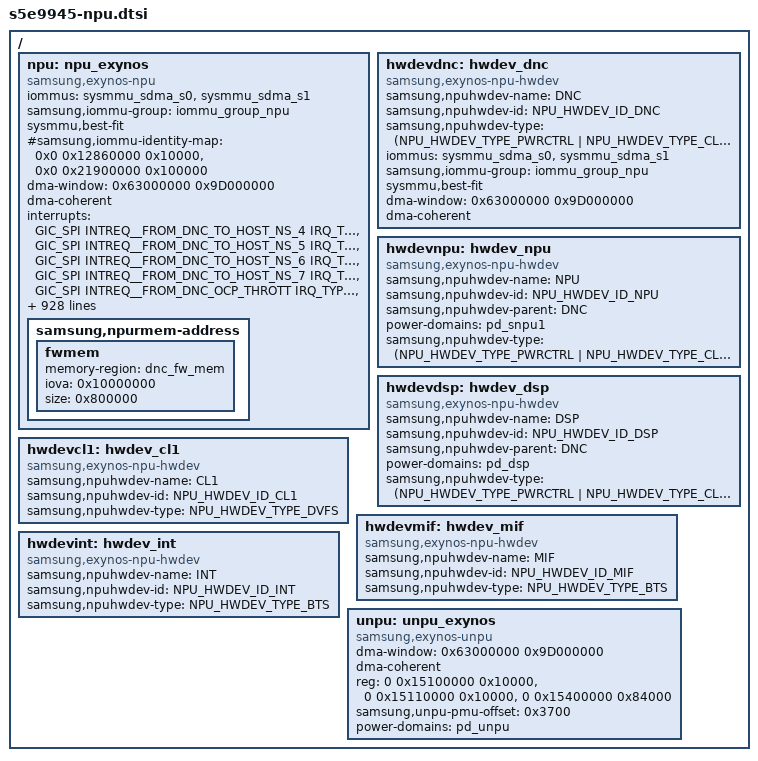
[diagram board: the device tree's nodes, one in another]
/*
 * SAMSUNG EXYNOS9945 NPU device tree source
 *
 * Copyright (c) 2023 Samsung Electronics Co., Ltd.
 *		http://www.samsung.com
 *
 * SAMSUNG EXYNOS9945 NPU device nodes are listed in this file.
 * EXYNOS based board files can include this file and provide
 * values for board specfic bindings.
 *
 * This program is free software; you can redistribute it and/or modify
 * it under the terms of the GNU General Public License version 2 as
 * published by the Free Software Foundation.
 */
#include <dt-bindings/clock/s5e9945.h>
#include <dt-bindings/soc/samsung/s5e9945-npu.h>

/ {
	npu: npu_exynos {
		compatible = "samsung,exynos-npu";
		iommus = <&sysmmu_sdma_s0>, <&sysmmu_sdma_s1>;
		samsung,iommu-group = <&iommu_group_npu>;
		sysmmu,best-fit;
		#samsung,iommu-identity-map = <0x0 0x12860000 0x10000>, <0x0 0x21900000 0x100000>;
		#dma-address-cells = <1>;
		#dma-size-cells = <1>;
		dma-window = <0x63000000 0x9D000000>;
		dma-coherent;

		interrupts =
			<GIC_SPI INTREQ__FROM_DNC_TO_HOST_NS_4 IRQ_TYPE_LEVEL_HIGH>,
			<GIC_SPI INTREQ__FROM_DNC_TO_HOST_NS_5 IRQ_TYPE_LEVEL_HIGH>,
			<GIC_SPI INTREQ__FROM_DNC_TO_HOST_NS_6 IRQ_TYPE_LEVEL_HIGH>,
			<GIC_SPI INTREQ__FROM_DNC_TO_HOST_NS_7 IRQ_TYPE_LEVEL_HIGH>,
			<GIC_SPI INTREQ__FROM_DNC_OCP_THROTT IRQ_TYPE_LEVEL_HIGH>,
			<GIC_SPI INTREQ__HTU_GNPU1 IRQ_TYPE_LEVEL_HIGH>;

		samsung,npusys-corenum = <2>;
		/* refer to npu-system.h for memory names
		 * you can add init settings for each memory area
		 */
		samsung,npumem-address = /* 0 start      size */
			<0 0x20000000 0x100000>,
			<0 0x20100000 0x100000>,
			<0 0x20200000 0x100000>,
			<0 0x20300000 0x100000>,
			<0 0x20400000 0x100000>,
			<0 0x20500000 0x100000>,
			<0 0x20600000 0x100000>,

			<0 0x21000000 0x200000>,
			<0 0x21200000 0x200000>,
			<0 0x21400000 0x100000>,
			<0 0x21500000 0x100000>,
			<0 0x21600000 0x100000>,
			<0 0x21700000 0x100000>,
			<0 0x21800000 0x100000>,
			<0 0x21900000 0x100000>,

			<0 0x12860000 0x10000>,

			<0 0x22B00000 0x100000>,

			<0 0x400D000 0x1000>,
			<0 0x400B000 0x1000>,
			<0 0x400C000 0x1000>,
			<0x50640000 0x100C0110 0x1000>, /* 0x5064_0000 is right by fw side, 100? 110? */

			<0 0x20020000 0x1000>,
			<0 0x2002084C 0x100>,
			<0 0x20022000 0x4000>,
			<0 0x20020838 0x100>,
			<0 0x210D0000 0x1000>,
			<0 0x216D0000 0x1000>,

			<0 0x11100000 0x200000>,
			<2 0x11300000 0x1000000>,
			<0 0x13300000 0x800000>,
			<0 0x14000000 0x1000000>,
			<0 0x10D00000 0x100000>,
			<0 0x10E00000 0x200000>,
			<0 0x11000000 0x1000>,
			<0 0x11001000 0x7000>,
			<0 0x11008000 0xF8000>,
			<0 0x22000000 0x40000000>,
			<0 0x22000000 0x20000000>,
			<0 0x42000000 0x20000000>,
			<0 0x0 0x2800>;
		samsung,npumem-names =
				"sfrdnc",	"SFR",
				"sfrsdma",	"SFR",
				"sfrgnpu0",	"SFR",
				"sfrgnpu1",	"SFR",
				"sfrdsp0",	"SFR",
				"sfrsnpu0",	"SFR",
				"sfrsnpu1",	"SFR",

				"sfrblkdnc",	"SFR",
				"sfrblksdma",	"SFR",
				"sfrblkdsp0",	"SFR",
				"sfrblkgnpu0",	"SFR",
				"sfrblkgnpu1",	"SFR",
				"sfrblksnpu0",	"SFR",
				"sfrblksnpu1",	"SFR",
				"sfrblknpumem",	"SFR",

				"sfrpmualive",	"SFR",

				"sfrfreq",	"SFR",

				"sfrcoresight",	"SFR",
				"sfrstm",	"SFR",
				"sfrstm1",	"SFR",
				"sfrmctg",	"SFR",

				"sfrmbox",	"SFR",
				"sfrmbox0",	"SFR",
				"sfrmbox1",	"SFR",
				"sfrmbox2",	"SFR",
				"htudnc",	"SFR",
				"htugnpu1",	"SFR",

				"fwmbox",	"fwmbox",
				"llc",		"llc",
				"fwunittest",	"fwunittest",
				"ivp_pm",	"dsp_ivp_pm.bin",
				"dl_out",	"dl_out",
				"dsp_mem",	"dsp_mem",
				"dhcp",		"dhcp",
				"ivp_dm",	"dsp_ivp_dm.bin",
				"fwlog",	"fwlog",
				"CHUNK_IMB",	"IMB",
				"CHUNK_IMBl",	"IMB",
				"CHUNK_IMBh",   "IMB",
				"CMDQ_TABLE",	"";

		/* examples of memory area init
		 *	offset,	val,	mask,
		 * samsung,npumem-baaw =
		 *	<0x00, 0x017B00, 0xFFFFFF>,
		 *	<0x00, 0x017B40, 0xFFFFFF>,
		 *	...;
		 */

		/* examples of reg cmd
		 *	sfr : name of memory area
		 *	data :
		 *	<rw	offset	val	mask	mdelay>,
		 */

		samsung,npucmd-acgennpum-sfr =
			"sfrblknpumem";
		samsung,npucmd-acgennpum-data =
			<1	0x800	0x301FF0BF	0xFFFFFFFF	0>;

		samsung,npucmd-acgdisnpum-sfr =
			"sfrblkdnc",
			"sfrblksdma",
			"sfrblknpumem",
			"sfrblkgnpu0",
			"sfrblkgnpu1",
			"sfrblksnpu0",
			"sfrblksnpu1";
		samsung,npucmd-acgdisnpum-data =
			<1	0x800	0xF01FF0BF	0xFFFFFFFF	0>,
			<1	0x800	0xF01FF0BF	0xFFFFFFFF	0>,
			<1	0x800	0x0		0xFFFFFFFF	0>,
			<1	0x800	0xF01FF0BF	0xFFFFFFFF	0>,
			<1	0x800	0xF01FF0BF	0xFFFFFFFF	0>,
			<1	0x800	0xF01FF0BF	0xFFFFFFFF	0>,
			<1	0x800	0xF01FF0BF	0xFFFFFFFF	0>;

		samsung,npucmd-acgendsp-sfr =
			"sfrblkdsp0";
		samsung,npucmd-acgendsp-data =
			<1	0x800	0xF01FF0BF	0xFFFFFFFF	0>;

		samsung,npucmd-acgenall-sfr =
			"sfrblkdnc",
			"sfrblksdma",
			"sfrblknpumem",
			"sfrblkgnpu0",
			"sfrblkgnpu1",
			"sfrblksnpu0",
			"sfrblksnpu1";
		samsung,npucmd-acgenall-data =
			<1	0x800	0xF01FF0BF	0xFFFFFFFF	0>,
			<1	0x800	0xF01FF0BF	0xFFFFFFFF	0>,
			<1	0x800	0xF01FF0BF	0xFFFFFFFF	0>,
			<1	0x800	0xF01FF0BF	0xFFFFFFFF	0>,
			<1	0x800	0xF01FF0BF	0xFFFFFFFF	0>,
			<1	0x800	0xF01FF0BF	0xFFFFFFFF	0>,
			<1	0x800	0xF01FF0BF	0xFFFFFFFF	0>;

		samsung,npucmd-acgdisall-sfr =
		/* sfrblkdnc */
			"sfrblkdnc",
			"sfrblkdnc",
			"sfrblkdnc",
			"sfrblkdnc",
			"sfrblkdnc",
			"sfrblkdnc",
			"sfrblkdnc",
			"sfrblkdnc",
			"sfrblkdnc",
			"sfrblkdnc",
			"sfrblkdnc",
			"sfrblkdnc",
		/* sfrblksdma */
			"sfrblksdma",
			"sfrblksdma",
			"sfrblksdma",
			"sfrblksdma",
			"sfrblksdma",
			"sfrblksdma",
			"sfrblksdma",
			"sfrblksdma",
			"sfrblksdma",
			"sfrblksdma",
		/* sfrblknpumem */
			"sfrblknpumem",
			"sfrblknpumem",
			"sfrblknpumem",
			"sfrblknpumem",
			"sfrblknpumem",
			"sfrblknpumem",
			"sfrblknpumem",
			"sfrblknpumem",
			"sfrblknpumem",
			"sfrblknpumem",
		/* sfrblkdsp0 */
			"sfrblkdsp0",
			"sfrblkdsp0",
			"sfrblkdsp0",
		/* sfrblkgnpu0 */
			"sfrblkgnpu0",
			"sfrblkgnpu0",
			"sfrblkgnpu0",
			"sfrblkgnpu0",
			"sfrblkgnpu0",
			"sfrblkgnpu0",
			"sfrblkgnpu0",
		/* sfrblkgnpu1 */
			"sfrblkgnpu1",
			"sfrblkgnpu1",
			"sfrblkgnpu1",
			"sfrblkgnpu1",
			"sfrblkgnpu1",
			"sfrblkgnpu1",
			"sfrblkgnpu1",
		/* sfrblksnpu0 */
			"sfrblksnpu0",
			"sfrblksnpu0",
			"sfrblksnpu0",
			"sfrblksnpu0",
			"sfrblksnpu0",
			"sfrblksnpu0",
			"sfrblksnpu0",
		/* sfrblksnpu1 */
			"sfrblksnpu1",
			"sfrblksnpu1",
			"sfrblksnpu1",
			"sfrblksnpu1",
			"sfrblksnpu1",
			"sfrblksnpu1",
			"sfrblksnpu1";
		samsung,npucmd-acgdisall-data =
		/* sfrblkdnc */
			<1	0x800	0x0	0xFFFFFFFF	0>,
			<1	0x20104	0x0	0xFFFFFFFF	0>,
			<1	0x2040C	0x0	0xFFFFFFFF	0>,
			<1	0x20410	0x0	0xFFFFFFFF	0>,
			<1	0x20414	0x0	0xFFFFFFFF	0>,
			<1	0x20418	0x0	0xFFFFFFFF	0>,
			<1	0x2041C	0x0	0xFFFFFFFF	0>,
			<1	0x20420	0x0	0xFFFFFFFF	0>,
			<1	0x20424	0x0	0xFFFFFFFF	0>,
			<1	0x20428	0x0	0xFFFFFFFF	0>,
			<1	0x2042C	0x0	0xFFFFFFFF	0>,
			<1	0x20430	0x0	0xFFFFFFFF	0>,
		/* sfrblksdma */
			<1	0x800	0x0	0xFFFFFFFF	0>,
			<1	0x20400	0x0	0xFFFFFFFF	0>,
			<1	0x20404	0x0	0xFFFFFFFF	0>,
			<1	0x20410	0x0	0xFFFFFFFF	0>,
			<1	0x20418	0x0	0xFFFFFFFF	0>,
			<1	0x2041C	0x0	0xFFFFFFFF	0>,
			<1	0x20420	0x0	0xFFFFFFFF	0>,
			<1	0x20424	0x0	0xFFFFFFFF	0>,
			<1	0x20428	0x0	0xFFFFFFFF	0>,
			<1	0x2042C	0x0	0xFFFFFFFF	0>,
		/* sfrblknpumem */
			<1	0x800	0x0	0xFFFFFFFF	0>,
			<1	0x20104	0x0	0xFFFFFFFF	0>,
			<1	0x20400	0x0	0xFFFFFFFF	0>,
			<1	0x20404	0x0	0xFFFFFFFF	0>,
			<1	0x20408	0x0	0xFFFFFFFF	0>,
			<1	0x2040C	0x0	0xFFFFFFFF	0>,
			<1	0x20410	0x0	0xFFFFFFFF	0>,
			<1	0x20414	0x0	0xFFFFFFFF	0>,
			<1	0x20418	0x0	0xFFFFFFFF	0>,
			<1	0x2041C	0x0	0xFFFFFFFF	0>,
		/* sfrblkdsp0 */
			<1	0x800	0x0	0xFFFFFFFF	0>,
			<1	0x20104	0x0	0xFFFFFFFF	0>,
			<1	0x20420	0x0	0xFFFFFFFF	0>,
		/* sfrblkgnpu0 */
			<1	0x800	0x0	0xFFFFFFFF	0>,
			<1	0x20104	0x0	0xFFFFFFFF	0>,
			<1	0x20400	0x0	0xFFFFFFFF	0>,
			<1	0x20404	0x0	0xFFFFFFFF	0>,
			<1	0x20408	0x0	0xFFFFFFFF	0>,
			<1	0x2040C	0x0	0xFFFFFFFF	0>,
			<1	0x20410	0x0	0xFFFFFFFF	0>,
		/* sfrblkgnpu1 */
			<1	0x800	0x0	0xFFFFFFFF	0>,
			<1	0x20104	0x0	0xFFFFFFFF	0>,
			<1	0x20400	0x0	0xFFFFFFFF	0>,
			<1	0x20404	0x0	0xFFFFFFFF	0>,
			<1	0x20408	0x0	0xFFFFFFFF	0>,
			<1	0x2040C	0x0	0xFFFFFFFF	0>,
			<1	0x20410	0x0	0xFFFFFFFF	0>,
		/* sfrblksnpu0 */
			<1	0x800	0x0	0xFFFFFFFF	0>,
			<1	0x20104	0x0	0xFFFFFFFF	0>,
			<1	0x20400	0x0	0xFFFFFFFF	0>,
			<1	0x20404	0x0	0xFFFFFFFF	0>,
			<1	0x20408	0x0	0xFFFFFFFF	0>,
			<1	0x2040C	0x0	0xFFFFFFFF	0>,
			<1	0x20410	0x0	0xFFFFFFFF	0>,
		/* sfrblksnpu1 */
			<1	0x800	0x0	0xFFFFFFFF	0>,
			<1	0x20104	0x0	0xFFFFFFFF	0>,
			<1	0x20400	0x0	0xFFFFFFFF	0>,
			<1	0x20404	0x0	0xFFFFFFFF	0>,
			<1	0x20408	0x0	0xFFFFFFFF	0>,
			<1	0x2040C	0x0	0xFFFFFFFF	0>,
			<1	0x20410	0x0	0xFFFFFFFF	0>;

		samsung,npucmd-hwacgenlh2-sfr =
			"sfrblknpumem",
			"sfrblknpumem",
			"sfrblknpumem",
			"sfrblknpumem",
			"sfrblknpumem",
			"sfrblknpumem",
			"sfrblknpumem",
			"sfrblknpumem",
			"sfrblknpumem",
			"sfrblknpumem",
			"sfrblknpumem",
			"sfrblknpumem",
			"sfrblknpumem",
			"sfrblknpumem",
			"sfrblknpumem",
			"sfrblknpumem",
			"sfrblknpumem",
			"sfrblknpumem",
			"sfrblknpumem",
			"sfrblknpumem",
			"sfrblknpumem",
			"sfrblknpumem",
			"sfrblknpumem",
			"sfrblknpumem",
			"sfrblknpumem",
			"sfrblknpumem",
			"sfrblknpumem",
			"sfrblknpumem",
			"sfrblknpumem",
			"sfrblknpumem",
			"sfrblknpumem",
			"sfrblknpumem",
			"sfrblknpumem",
			"sfrblknpumem",
			"sfrblknpumem",
			"sfrblknpumem",
			"sfrblknpumem",
			"sfrblknpumem",
			"sfrblknpumem",
			"sfrblknpumem";
		samsung,npucmd-hwacgenlh2-data =
			<1	0x3020	0x00000002	0xFFFFFFFF	0>,
			<1	0x3050	0x00000002	0xFFFFFFFF	0>,
			<1	0x3078	0x00000002	0xFFFFFFFF	0>,
			<1	0x30A0	0x00000002	0xFFFFFFFF	0>,
			<1	0x30C8	0x00000002	0xFFFFFFFF	0>,
			<1	0x30F0	0x00000002	0xFFFFFFFF	0>,
			<1	0x3118	0x00000002	0xFFFFFFFF	0>,
			<1	0x3140	0x00000002	0xFFFFFFFF	0>,
			<1	0x3168	0x00000002	0xFFFFFFFF	0>,
			<1	0x3178	0x00000002	0xFFFFFFFF	0>,
			<1	0x31A0	0x00000002	0xFFFFFFFF	0>,
			<1	0x31D0	0x00000002	0xFFFFFFFF	0>,
			<1	0x31F8	0x00000002	0xFFFFFFFF	0>,
			<1	0x3220	0x00000002	0xFFFFFFFF	0>,
			<1	0x3248	0x00000002	0xFFFFFFFF	0>,
			<1	0x3270	0x00000002	0xFFFFFFFF	0>,
			<1	0x3298	0x00000002	0xFFFFFFFF	0>,
			<1	0x32B0	0x00000002	0xFFFFFFFF	0>,
			<1	0x32C8	0x00000002	0xFFFFFFFF	0>,
			<1	0x32D8	0x00000002	0xFFFFFFFF	0>,
			<1	0x3300	0x00000002	0xFFFFFFFF	0>,
			<1	0x3330	0x00000002	0xFFFFFFFF	0>,
			<1	0x3358	0x00000002	0xFFFFFFFF	0>,
			<1	0x3380	0x00000002	0xFFFFFFFF	0>,
			<1	0x33A8	0x00000002	0xFFFFFFFF	0>,
			<1	0x33D0	0x00000002	0xFFFFFFFF	0>,
			<1	0x33F8	0x00000002	0xFFFFFFFF	0>,
			<1	0x3420	0x00000002	0xFFFFFFFF	0>,
			<1	0x3448	0x00000002	0xFFFFFFFF	0>,
			<1	0x3458	0x00000002	0xFFFFFFFF	0>,
			<1	0x3480	0x00000002	0xFFFFFFFF	0>,
			<1	0x34B0	0x00000002	0xFFFFFFFF	0>,
			<1	0x34D8	0x00000002	0xFFFFFFFF	0>,
			<1	0x3500	0x00000002	0xFFFFFFFF	0>,
			<1	0x3528	0x00000002	0xFFFFFFFF	0>,
			<1	0x3550	0x00000002	0xFFFFFFFF	0>,
			<1	0x3578	0x00000002	0xFFFFFFFF	0>,
			<1	0x3590	0x00000002	0xFFFFFFFF	0>,
			<1	0x35A8	0x00000002	0xFFFFFFFF	0>,
			<1	0x35B8	0x00000002	0xFFFFFFFF	0>;

		samsung,npucmd-hwacgdislh2-sfr =
			"sfrblknpumem",
			"sfrblknpumem",
			"sfrblknpumem",
			"sfrblknpumem",
			"sfrblknpumem",
			"sfrblknpumem",
			"sfrblknpumem",
			"sfrblknpumem",
			"sfrblknpumem",
			"sfrblknpumem",
			"sfrblknpumem",
			"sfrblknpumem",
			"sfrblknpumem",
			"sfrblknpumem",
			"sfrblknpumem",
			"sfrblknpumem",
			"sfrblknpumem",
			"sfrblknpumem",
			"sfrblknpumem",
			"sfrblknpumem",
			"sfrblknpumem",
			"sfrblknpumem",
			"sfrblknpumem",
			"sfrblknpumem",
			"sfrblknpumem",
			"sfrblknpumem",
			"sfrblknpumem",
			"sfrblknpumem",
			"sfrblknpumem",
			"sfrblknpumem",
			"sfrblknpumem",
			"sfrblknpumem",
			"sfrblknpumem",
			"sfrblknpumem",
			"sfrblknpumem",
			"sfrblknpumem",
			"sfrblknpumem",
			"sfrblknpumem",
			"sfrblknpumem",
			"sfrblknpumem";
		samsung,npucmd-hwacgdislh2-data =
			<1	0x3020	0x00000006	0xFFFFFFFF	0>,
			<1	0x3050	0x00000006	0xFFFFFFFF	0>,
			<1	0x3078	0x00000006	0xFFFFFFFF	0>,
			<1	0x30A0	0x00000006	0xFFFFFFFF	0>,
			<1	0x30C8	0x00000006	0xFFFFFFFF	0>,
			<1	0x30F0	0x00000006	0xFFFFFFFF	0>,
			<1	0x3118	0x00000006	0xFFFFFFFF	0>,
			<1	0x3140	0x00000006	0xFFFFFFFF	0>,
			<1	0x3168	0x00000006	0xFFFFFFFF	0>,
			<1	0x3178	0x00000006	0xFFFFFFFF	0>,
			<1	0x31A0	0x00000006	0xFFFFFFFF	0>,
			<1	0x31D0	0x00000006	0xFFFFFFFF	0>,
			<1	0x31F8	0x00000006	0xFFFFFFFF	0>,
			<1	0x3220	0x00000006	0xFFFFFFFF	0>,
			<1	0x3248	0x00000006	0xFFFFFFFF	0>,
			<1	0x3270	0x00000006	0xFFFFFFFF	0>,
			<1	0x3298	0x00000006	0xFFFFFFFF	0>,
			<1	0x32B0	0x00000006	0xFFFFFFFF	0>,
			<1	0x32C8	0x00000006	0xFFFFFFFF	0>,
			<1	0x32D8	0x00000006	0xFFFFFFFF	0>,
			<1	0x3300	0x00000006	0xFFFFFFFF	0>,
			<1	0x3330	0x00000006	0xFFFFFFFF	0>,
			<1	0x3358	0x00000006	0xFFFFFFFF	0>,
			<1	0x3380	0x00000006	0xFFFFFFFF	0>,
			<1	0x33A8	0x00000006	0xFFFFFFFF	0>,
			<1	0x33D0	0x00000006	0xFFFFFFFF	0>,
			<1	0x33F8	0x00000006	0xFFFFFFFF	0>,
			<1	0x3420	0x00000006	0xFFFFFFFF	0>,
			<1	0x3448	0x00000006	0xFFFFFFFF	0>,
			<1	0x3458	0x00000006	0xFFFFFFFF	0>,
			<1	0x3480	0x00000006	0xFFFFFFFF	0>,
			<1	0x34B0	0x00000006	0xFFFFFFFF	0>,
			<1	0x34D8	0x00000006	0xFFFFFFFF	0>,
			<1	0x3500	0x00000006	0xFFFFFFFF	0>,
			<1	0x3528	0x00000006	0xFFFFFFFF	0>,
			<1	0x3550	0x00000006	0xFFFFFFFF	0>,
			<1	0x3578	0x00000006	0xFFFFFFFF	0>,
			<1	0x3590	0x00000006	0xFFFFFFFF	0>,
			<1	0x35A8	0x00000006	0xFFFFFFFF	0>,
			<1	0x35B8	0x00000006	0xFFFFFFFF	0>;

		samsung,npucmd-hwacgenlh-sfr =
			"sfrblknpumem",
			"sfrblknpumem",
			"sfrblknpumem",
			"sfrblknpumem",
			"sfrblknpumem",
			"sfrblknpumem",
			"sfrblknpumem",
			"sfrblknpumem",
			"sfrblknpumem",
			"sfrblknpumem",
			"sfrblknpumem",
			"sfrblknpumem",
			"sfrblknpumem",
			"sfrblknpumem",
			"sfrblknpumem",
			"sfrblknpumem",
			"sfrblknpumem",
			"sfrblknpumem",
			"sfrblknpumem",
			"sfrblknpumem",
			"sfrblknpumem",
			"sfrblknpumem",
			"sfrblknpumem",
			"sfrblknpumem",
			"sfrblknpumem",
			"sfrblknpumem",
			"sfrblknpumem",
			"sfrblknpumem",
			"sfrblknpumem",
			"sfrblknpumem",
			"sfrblknpumem",
			"sfrblknpumem",
			"sfrblknpumem",
			"sfrblknpumem",
			"sfrblknpumem",
			"sfrblknpumem",
			"sfrblknpumem",
			"sfrblknpumem",
			"sfrblknpumem",
			"sfrblknpumem",
			"sfrblknpumem",
			"sfrblknpumem",
			"sfrblknpumem",
			"sfrblknpumem",
			"sfrblknpumem",
			"sfrblknpumem",
			"sfrblknpumem",
			"sfrblknpumem",
			"sfrblknpumem",
			"sfrblknpumem",
			"sfrblknpumem",
			"sfrblknpumem",
			"sfrblknpumem",
			"sfrblknpumem",
			"sfrblknpumem",
			"sfrblknpumem",
			"sfrblknpumem",
			"sfrblknpumem",
			"sfrblknpumem",
			"sfrblknpumem",
			"sfrblknpumem",
			"sfrblknpumem",
			"sfrblknpumem",
			"sfrblknpumem",
			"sfrblknpumem",
			"sfrblknpumem",
			"sfrblknpumem",
			"sfrblknpumem";
		samsung,npucmd-hwacgenlh-data =
			<1	0x3308	0x00000002	0xFFFFFFFF	0>,
			<1	0x3338	0x00000002	0xFFFFFFFF	0>,
			<1	0x3360	0x00000002	0xFFFFFFFF	0>,
			<1	0x3388	0x00000002	0xFFFFFFFF	0>,
			<1	0x33B0	0x00000002	0xFFFFFFFF	0>,
			<1	0x33D8	0x00000002	0xFFFFFFFF	0>,

			<1	0x33F0	0x00000002	0xFFFFFFFF	0>,
			<1	0x33F8	0x00000002	0xFFFFFFFF	0>,

			<1	0x3400	0x00000002	0xFFFFFFFF	0>,

			<1	0x3418	0x00000002	0xFFFFFFFF	0>,
			<1	0x3420	0x00000002	0xFFFFFFFF	0>,

			<1	0x3428	0x00000002	0xFFFFFFFF	0>,

			<1	0x3440	0x00000002	0xFFFFFFFF	0>,
			<1	0x3448	0x00000002	0xFFFFFFFF	0>,
			<1	0x3450	0x00000002	0xFFFFFFFF	0>,
			<1	0x3458	0x00000002	0xFFFFFFFF	0>,

			<1	0x3488	0x00000002	0xFFFFFFFF	0>,
			<1	0x34B8	0x00000002	0xFFFFFFFF	0>,
			<1	0x34E0	0x00000002	0xFFFFFFFF	0>,
			<1	0x3508	0x00000002	0xFFFFFFFF	0>,
			<1	0x3530	0x00000002	0xFFFFFFFF	0>,
			<1	0x3558	0x00000002	0xFFFFFFFF	0>,
			<1	0x3570	0x00000002	0xFFFFFFFF	0>,
			<1	0x3578	0x00000002	0xFFFFFFFF	0>,
			<1	0x3580	0x00000002	0xFFFFFFFF	0>,
			<1	0x3588	0x00000002	0xFFFFFFFF	0>,
			<1	0x3590	0x00000002	0xFFFFFFFF	0>,
			<1	0x3598	0x00000002	0xFFFFFFFF	0>,
			<1	0x35A0	0x00000002	0xFFFFFFFF	0>,
			<1	0x35A8	0x00000002	0xFFFFFFFF	0>,
			<1	0x35B0	0x00000002	0xFFFFFFFF	0>,
			<1	0x35B8	0x00000002	0xFFFFFFFF	0>,

			<1	0x3028	0x00000002	0xFFFFFFFF	0>,
			<1	0x3058	0x00000002	0xFFFFFFFF	0>,
			<1	0x3080	0x00000002	0xFFFFFFFF	0>,
			<1	0x30A8	0x00000002	0xFFFFFFFF	0>,
			<1	0x30D0	0x00000002	0xFFFFFFFF	0>,
			<1	0x30F8	0x00000002	0xFFFFFFFF	0>,
			<1	0x3110	0x00000002	0xFFFFFFFF	0>,
			<1	0x3118	0x00000002	0xFFFFFFFF	0>,
			<1	0x3120	0x00000002	0xFFFFFFFF	0>,
			<1	0x3138	0x00000002	0xFFFFFFFF	0>,
			<1	0x3140	0x00000002	0xFFFFFFFF	0>,
			<1	0x3148	0x00000002	0xFFFFFFFF	0>,
			<1	0x3160	0x00000002	0xFFFFFFFF	0>,
			<1	0x3168	0x00000002	0xFFFFFFFF	0>,
			<1	0x3170	0x00000002	0xFFFFFFFF	0>,
			<1	0x3178	0x00000002	0xFFFFFFFF	0>,
			<1	0x31A8	0x00000002	0xFFFFFFFF	0>,
			<1	0x31D8	0x00000002	0xFFFFFFFF	0>,
			<1	0x3200	0x00000002	0xFFFFFFFF	0>,
			<1	0x3228	0x00000002	0xFFFFFFFF	0>,
			<1	0x3250	0x00000002	0xFFFFFFFF	0>,
			<1	0x3278	0x00000002	0xFFFFFFFF	0>,
			<1	0x3290	0x00000002	0xFFFFFFFF	0>,
			<1	0x3298	0x00000002	0xFFFFFFFF	0>,
			<1	0x32A0	0x00000002	0xFFFFFFFF	0>,
			<1	0x32A8	0x00000002	0xFFFFFFFF	0>,
			<1	0x32B0	0x00000002	0xFFFFFFFF	0>,
			<1	0x32B8	0x00000002	0xFFFFFFFF	0>,
			<1	0x32C0	0x00000002	0xFFFFFFFF	0>,
			<1	0x32C8	0x00000002	0xFFFFFFFF	0>,
			<1	0x32D0	0x00000002	0xFFFFFFFF	0>,
			<1	0x32D8	0x00000002	0xFFFFFFFF	0>,

			<1	0x3180	0x00000002	0xFFFFFFFF	0>,
			<1	0x32E0	0x00000002	0xFFFFFFFF	0>,
			<1	0x32E8	0x00000002	0xFFFFFFFF	0>,
			<1	0x3460	0x00000002	0xFFFFFFFF	0>;


		samsung,npucmd-hwacgdislh-sfr =
			"sfrblknpumem",
			"sfrblknpumem",
			"sfrblknpumem",
			"sfrblknpumem",
			"sfrblknpumem",
			"sfrblknpumem",
			"sfrblknpumem",
			"sfrblknpumem",
			"sfrblknpumem",
			"sfrblknpumem",
			"sfrblknpumem",
			"sfrblknpumem",
			"sfrblknpumem",
			"sfrblknpumem",
			"sfrblknpumem",
			"sfrblknpumem",
			"sfrblknpumem",
			"sfrblknpumem",
			"sfrblknpumem",
			"sfrblknpumem",
			"sfrblknpumem",
			"sfrblknpumem",
			"sfrblknpumem",
			"sfrblknpumem",
			"sfrblknpumem",
			"sfrblknpumem",
			"sfrblknpumem",
			"sfrblknpumem",
			"sfrblknpumem",
			"sfrblknpumem",
			"sfrblknpumem",
			"sfrblknpumem",
			"sfrblknpumem",
			"sfrblknpumem",
			"sfrblknpumem",
			"sfrblknpumem",
			"sfrblknpumem",
			"sfrblknpumem",
			"sfrblknpumem",
			"sfrblknpumem",
			"sfrblknpumem",
			"sfrblknpumem",
			"sfrblknpumem",
			"sfrblknpumem",
			"sfrblknpumem",
			"sfrblknpumem",
			"sfrblknpumem",
			"sfrblknpumem",
			"sfrblknpumem",
			"sfrblknpumem",
			"sfrblknpumem",
			"sfrblknpumem",
			"sfrblknpumem",
			"sfrblknpumem",
			"sfrblknpumem",
			"sfrblknpumem",
			"sfrblknpumem",
			"sfrblknpumem",
			"sfrblknpumem",
			"sfrblknpumem",
			"sfrblknpumem",
			"sfrblknpumem",
			"sfrblknpumem",
			"sfrblknpumem",
			"sfrblknpumem",
			"sfrblknpumem",
			"sfrblknpumem",
			"sfrblknpumem";
		samsung,npucmd-hwacgdislh-data =
			<1	0x3308	0x00000006	0xFFFFFFFF	0>,
			<1	0x3338	0x00000006	0xFFFFFFFF	0>,
			<1	0x3360	0x00000006	0xFFFFFFFF	0>,
			<1	0x3388	0x00000006	0xFFFFFFFF	0>,
			<1	0x33B0	0x00000006	0xFFFFFFFF	0>,
			<1	0x33D8	0x00000006	0xFFFFFFFF	0>,

			<1	0x33F0	0x00000006	0xFFFFFFFF	0>,
			<1	0x33F8	0x00000006	0xFFFFFFFF	0>,

			<1	0x3400	0x00000006	0xFFFFFFFF	0>,

			<1	0x3418	0x00000006	0xFFFFFFFF	0>,
			<1	0x3420	0x00000006	0xFFFFFFFF	0>,

			<1	0x3428	0x00000006	0xFFFFFFFF	0>,

			<1	0x3440	0x00000006	0xFFFFFFFF	0>,
			<1	0x3448	0x00000006	0xFFFFFFFF	0>,
			<1	0x3450	0x00000006	0xFFFFFFFF	0>,
			<1	0x3458	0x00000006	0xFFFFFFFF	0>,

			<1	0x3488	0x00000006	0xFFFFFFFF	0>,
			<1	0x34B8	0x00000006	0xFFFFFFFF	0>,
			<1	0x34E0	0x00000006	0xFFFFFFFF	0>,
			<1	0x3508	0x00000006	0xFFFFFFFF	0>,
			<1	0x3530	0x00000006	0xFFFFFFFF	0>,
			<1	0x3558	0x00000006	0xFFFFFFFF	0>,
			<1	0x3570	0x00000006	0xFFFFFFFF	0>,
			<1	0x3578	0x00000006	0xFFFFFFFF	0>,
			<1	0x3580	0x00000006	0xFFFFFFFF	0>,
			<1	0x3588	0x00000006	0xFFFFFFFF	0>,
			<1	0x3590	0x00000006	0xFFFFFFFF	0>,
			<1	0x3598	0x00000006	0xFFFFFFFF	0>,
			<1	0x35A0	0x00000006	0xFFFFFFFF	0>,
			<1	0x35A8	0x00000006	0xFFFFFFFF	0>,
			<1	0x35B0	0x00000006	0xFFFFFFFF	0>,
			<1	0x35B8	0x00000006	0xFFFFFFFF	0>,

			<1	0x3028	0x00000006	0xFFFFFFFF	0>,
			<1	0x3058	0x00000006	0xFFFFFFFF	0>,
			<1	0x3080	0x00000006	0xFFFFFFFF	0>,
			<1	0x30A8	0x00000006	0xFFFFFFFF	0>,
			<1	0x30D0	0x00000006	0xFFFFFFFF	0>,
			<1	0x30F8	0x00000006	0xFFFFFFFF	0>,
			<1	0x3110	0x00000006	0xFFFFFFFF	0>,
			<1	0x3118	0x00000006	0xFFFFFFFF	0>,
			<1	0x3120	0x00000006	0xFFFFFFFF	0>,
			<1	0x3138	0x00000006	0xFFFFFFFF	0>,
			<1	0x3140	0x00000006	0xFFFFFFFF	0>,
			<1	0x3148	0x00000006	0xFFFFFFFF	0>,
			<1	0x3160	0x00000006	0xFFFFFFFF	0>,
			<1	0x3168	0x00000006	0xFFFFFFFF	0>,
			<1	0x3170	0x00000006	0xFFFFFFFF	0>,
			<1	0x3178	0x00000006	0xFFFFFFFF	0>,
			<1	0x31A8	0x00000006	0xFFFFFFFF	0>,
			<1	0x31D8	0x00000006	0xFFFFFFFF	0>,
			<1	0x3200	0x00000006	0xFFFFFFFF	0>,
			<1	0x3228	0x00000006	0xFFFFFFFF	0>,
			<1	0x3250	0x00000006	0xFFFFFFFF	0>,
			<1	0x3278	0x00000006	0xFFFFFFFF	0>,
			<1	0x3290	0x00000006	0xFFFFFFFF	0>,
			<1	0x3298	0x00000006	0xFFFFFFFF	0>,
			<1	0x32A0	0x00000006	0xFFFFFFFF	0>,
			<1	0x32A8	0x00000006	0xFFFFFFFF	0>,
			<1	0x32B0	0x00000006	0xFFFFFFFF	0>,
			<1	0x32B8	0x00000006	0xFFFFFFFF	0>,
			<1	0x32C0	0x00000006	0xFFFFFFFF	0>,
			<1	0x32C8	0x00000006	0xFFFFFFFF	0>,
			<1	0x32D0	0x00000006	0xFFFFFFFF	0>,
			<1	0x32D8	0x00000006	0xFFFFFFFF	0>,

			<1	0x3180	0x00000006	0xFFFFFFFF	0>,
			<1	0x32E0	0x00000006	0xFFFFFFFF	0>,
			<1	0x32E8	0x00000006	0xFFFFFFFF	0>,
			<1	0x3460	0x00000006	0xFFFFFFFF	0>;
		samsung,npucmd-hwacgendnc-sfr =
		/* sfrblkdnc */
			"sfrblkdnc",
		/* sfrblksdma */
			"sfrblksdma";
		samsung,npucmd-hwacgendnc-data =
		/* sfrblkdnc */
			<1	0x800	0xF01FF0BF	0xFFFFFFFF	0>,
		/* sfrblksdma */
			<1	0x800	0xF01FF0BF	0xFFFFFFFF	0>;

		samsung,npucmd-hwacgennpu-sfr =
			"sfrblkdnc",
			"sfrblksdma",
			"sfrblknpumem",
			"sfrblkgnpu0",
			"sfrblkgnpu1",
			"sfrblksnpu0",
			"sfrblksnpu1";
		samsung,npucmd-hwacgennpu-data =
			<1	0x800	0xF01FF0BF	0xFFFFFFFF	0>,
			<1	0x800	0xF01FF0BF	0xFFFFFFFF	0>,
			<1	0x800	0xF01FF0BF	0xFFFFFFFF	0>,
			<1	0x800	0xF01FF0BF	0xFFFFFFFF	0>,
			<1	0x800	0xF01FF0BF	0xFFFFFFFF	0>,
			<1	0x800	0xF01FF0BF	0xFFFFFFFF	0>,
			<1	0x800	0xF01FF0BF	0xFFFFFFFF	0>,
			<1	0x800	0xF01FF0BF	0xFFFFFFFF	0>;

		samsung,npucmd-hwacgendsp-sfr =
			"sfrblkdsp0";
		samsung,npucmd-hwacgendsp-data =
			<1	0x800	0xF01FF0BF	0xFFFFFFFF	0>;

		samsung,npucmd-hwacgdisdnc-sfr =
		/* sfrblkdnc */
			"sfrblkdnc",
			"sfrblkdnc",
			"sfrblkdnc",
			"sfrblkdnc",
			"sfrblkdnc",
			"sfrblkdnc",
			"sfrblkdnc",
			"sfrblkdnc",
			"sfrblkdnc",
			"sfrblkdnc",
			"sfrblkdnc",
			"sfrblkdnc",
		/* sfrblksdma */
			"sfrblksdma",
			"sfrblksdma",
			"sfrblksdma",
			"sfrblksdma",
			"sfrblksdma",
			"sfrblksdma",
			"sfrblksdma",
			"sfrblksdma",
			"sfrblksdma",
			"sfrblksdma";
		samsung,npucmd-hwacgdisdnc-data =
		/* sfrblkdnc */
			<1	0x800	0x0	0xFFFFFFFF	0>,
			<1	0x20104	0x0	0xFFFFFFFF	0>,
			<1	0x2040C	0x0	0xFFFFFFFF	0>,
			<1	0x20410	0x0	0xFFFFFFFF	0>,
			<1	0x20414	0x0	0xFFFFFFFF	0>,
			<1	0x20418	0x0	0xFFFFFFFF	0>,
			<1	0x2041C	0x0	0xFFFFFFFF	0>,
			<1	0x20420	0x0	0xFFFFFFFF	0>,
			<1	0x20424	0x0	0xFFFFFFFF	0>,
			<1	0x20428	0x0	0xFFFFFFFF	0>,
			<1	0x2042C	0x0	0xFFFFFFFF	0>,
			<1	0x20430	0x0	0xFFFFFFFF	0>,
		/* sfrblksdma */
			<1	0x800	0x0	0xFFFFFFFF	0>,
			<1	0x20400	0x0	0xFFFFFFFF	0>,
			<1	0x20404	0x0	0xFFFFFFFF	0>,
			<1	0x20410	0x0	0xFFFFFFFF	0>,
			<1	0x20418	0x0	0xFFFFFFFF	0>,
			<1	0x2041C	0x0	0xFFFFFFFF	0>,
			<1	0x20420	0x0	0xFFFFFFFF	0>,
			<1	0x20424	0x0	0xFFFFFFFF	0>,
			<1	0x20428	0x0	0xFFFFFFFF	0>,
			<1	0x2042C	0x0	0xFFFFFFFF	0>;

		samsung,npucmd-hwacgdisnpu-sfr =
		/* sfrblkdnc */
			"sfrblkdnc",
			"sfrblkdnc",
			"sfrblkdnc",
			"sfrblkdnc",
			"sfrblkdnc",
			"sfrblkdnc",
			"sfrblkdnc",
			"sfrblkdnc",
			"sfrblkdnc",
			"sfrblkdnc",
			"sfrblkdnc",
			"sfrblkdnc",
		/* sfrblksdma */
			"sfrblksdma",
			"sfrblksdma",
			"sfrblksdma",
			"sfrblksdma",
			"sfrblksdma",
			"sfrblksdma",
			"sfrblksdma",
			"sfrblksdma",
			"sfrblksdma",
			"sfrblksdma",
		/* sfrblknpumem */
			"sfrblknpumem",
			"sfrblknpumem",
			"sfrblknpumem",
			"sfrblknpumem",
			"sfrblknpumem",
			"sfrblknpumem",
			"sfrblknpumem",
			"sfrblknpumem",
			"sfrblknpumem",
			"sfrblknpumem",
		/* sfrblkgnpu0 */
			"sfrblkgnpu0",
			"sfrblkgnpu0",
			"sfrblkgnpu0",
			"sfrblkgnpu0",
			"sfrblkgnpu0",
			"sfrblkgnpu0",
			"sfrblkgnpu0",
		/* sfrblkgnpu1 */
			"sfrblkgnpu1",
			"sfrblkgnpu1",
			"sfrblkgnpu1",
			"sfrblkgnpu1",
			"sfrblkgnpu1",
			"sfrblkgnpu1",
			"sfrblkgnpu1",
		/* sfrblksnpu0 */
			"sfrblksnpu0",
			"sfrblksnpu0",
			"sfrblksnpu0",
			"sfrblksnpu0",
			"sfrblksnpu0",
			"sfrblksnpu0",
			"sfrblksnpu0",
		/* sfrblksnpu1 */
			"sfrblksnpu1",
			"sfrblksnpu1",
			"sfrblksnpu1",
			"sfrblksnpu1",
			"sfrblksnpu1",
			"sfrblksnpu1",
			"sfrblksnpu1";
		samsung,npucmd-hwacgdisnpu-data =
		/* sfrblkdnc */
			<1	0x800	0x0	0xFFFFFFFF	0>,
			<1	0x20104	0x0	0xFFFFFFFF	0>,
			<1	0x2040C	0x0	0xFFFFFFFF	0>,
			<1	0x20410	0x0	0xFFFFFFFF	0>,
			<1	0x20414	0x0	0xFFFFFFFF	0>,
			<1	0x20418	0x0	0xFFFFFFFF	0>,
			<1	0x2041C	0x0	0xFFFFFFFF	0>,
			<1	0x20420	0x0	0xFFFFFFFF	0>,
			<1	0x20424	0x0	0xFFFFFFFF	0>,
			<1	0x20428	0x0	0xFFFFFFFF	0>,
			<1	0x2042C	0x0	0xFFFFFFFF	0>,
			<1	0x20430	0x0	0xFFFFFFFF	0>,
		/* sfrblksdma */
			<1	0x800	0x0	0xFFFFFFFF	0>,
			<1	0x20400	0x0	0xFFFFFFFF	0>,
			<1	0x20404	0x0	0xFFFFFFFF	0>,
			<1	0x20410	0x0	0xFFFFFFFF	0>,
			<1	0x20418	0x0	0xFFFFFFFF	0>,
			<1	0x2041C	0x0	0xFFFFFFFF	0>,
			<1	0x20420	0x0	0xFFFFFFFF	0>,
			<1	0x20424	0x0	0xFFFFFFFF	0>,
			<1	0x20428	0x0	0xFFFFFFFF	0>,
			<1	0x2042C	0x0	0xFFFFFFFF	0>,
		/* sfrblknpumem */
			<1	0x800	0x0	0xFFFFFFFF	0>,
			<1	0x20104	0x0	0xFFFFFFFF	0>,
			<1	0x20400	0x0	0xFFFFFFFF	0>,
			<1	0x20404	0x0	0xFFFFFFFF	0>,
			<1	0x20408	0x0	0xFFFFFFFF	0>,
			<1	0x2040C	0x0	0xFFFFFFFF	0>,
			<1	0x20410	0x0	0xFFFFFFFF	0>,
			<1	0x20414	0x0	0xFFFFFFFF	0>,
			<1	0x20418	0x0	0xFFFFFFFF	0>,
			<1	0x2041C	0x0	0xFFFFFFFF	0>,
		/* sfrblkgnpu0 */
			<1	0x800	0x0	0xFFFFFFFF	0>,
			<1	0x20104	0x0	0xFFFFFFFF	0>,
			<1	0x20400	0x0	0xFFFFFFFF	0>,
			<1	0x20404	0x0	0xFFFFFFFF	0>,
			<1	0x20408	0x0	0xFFFFFFFF	0>,
			<1	0x2040C	0x0	0xFFFFFFFF	0>,
			<1	0x20410	0x0	0xFFFFFFFF	0>,
		/* sfrblkgnpu1 */
			<1	0x800	0x0	0xFFFFFFFF	0>,
			<1	0x20104	0x0	0xFFFFFFFF	0>,
			<1	0x20400	0x0	0xFFFFFFFF	0>,
			<1	0x20404	0x0	0xFFFFFFFF	0>,
			<1	0x20408	0x0	0xFFFFFFFF	0>,
			<1	0x2040C	0x0	0xFFFFFFFF	0>,
			<1	0x20410	0x0	0xFFFFFFFF	0>,
		/* sfrblksnpu0 */
			<1	0x800	0x0	0xFFFFFFFF	0>,
			<1	0x20104	0x0	0xFFFFFFFF	0>,
			<1	0x20400	0x0	0xFFFFFFFF	0>,
			<1	0x20404	0x0	0xFFFFFFFF	0>,
			<1	0x20408	0x0	0xFFFFFFFF	0>,
			<1	0x2040C	0x0	0xFFFFFFFF	0>,
			<1	0x20410	0x0	0xFFFFFFFF	0>,
		/* sfrblksnpu1 */
			<1	0x800	0x0	0xFFFFFFFF	0>,
			<1	0x20104	0x0	0xFFFFFFFF	0>,
			<1	0x20400	0x0	0xFFFFFFFF	0>,
			<1	0x20404	0x0	0xFFFFFFFF	0>,
			<1	0x20408	0x0	0xFFFFFFFF	0>,
			<1	0x2040C	0x0	0xFFFFFFFF	0>,
			<1	0x20410	0x0	0xFFFFFFFF	0>;

		samsung,npucmd-hwacgdisdsp-sfr =
		/* sfrblkdsp0 */
			"sfrblkdsp0",
			"sfrblkdsp0",
			"sfrblkdsp0";
		samsung,npucmd-hwacgdisdsp-data =
		/* sfrblkdsp0 */
			<1	0x800	0x0	0xFFFFFFFF	0>,
			<1	0x20104	0x0	0xFFFFFFFF	0>,
			<1	0x20420	0x0	0xFFFFFFFF	0>;

		samsung,npucmd-npupgon-sfr =
			"sfrblksdma",
			"sfrblknpumem",
			"sfrblkgnpu0",
			"sfrblkgnpu1",
			"sfrblksnpu0",
			"sfrblksnpu1";
		samsung,npucmd-npupgon-data =
			<1	0x30000	0x1	0x00000001	0>,
			<1	0x40000	0x1	0x00000001	0>,
			<1	0x40000	0x1	0x00000001	0>,
			<1	0x40000	0x1	0x00000001	0>,
			<1	0x40000	0x1	0x00000001	0>,
			<1	0x40000	0x1	0x00000001	0>;

		samsung,npucmd-dsppgon-sfr =
			"sfrblksdma",
			"sfrblkdsp0";
		samsung,npucmd-dsppgon-data =
			<1	0x30000	0x1	0x00000001	0>,
			<1	0x30000	0x1	0x00000001	0>;

		samsung,npucmd-npupgoff-sfr =
			"sfrblksdma",
			"sfrblknpumem",
			"sfrblkgnpu0",
			"sfrblkgnpu1",
			"sfrblksnpu0",
			"sfrblksnpu1";
		samsung,npucmd-npupgoff-data =
			<1	0x30000	0x0	0x00000001	0>,
			<1	0x40000	0x0	0x00000001	0>,
			<1	0x40000	0x0	0x00000001	0>,
			<1	0x40000	0x0	0x00000001	0>,
			<1	0x40000	0x0	0x00000001	0>,
			<1	0x40000	0x0	0x00000001	0>;

		samsung,npucmd-dsppgoff-sfr =
			"sfrblksdma",
			"sfrblkdsp0";
		samsung,npucmd-dsppgoff-data =
			<1	0x30000	0x0	0x00000001	0>,
			<1	0x30000	0x0	0x00000001	0>;

		samsung,npucmd-cpuon-sfr =
			/* DNC boot up */
			"sfrdnc",
			"sfrdnc",
			"sfrdnc",
			"sfrdnc",
			"sfrdnc",
			"sfrdnc",
			"sfrdnc";
		/*	cmd	offset	value	mask		delay */
		samsung,npucmd-cpuon-data =
		/* to power on, DNC_CPU_ALIVE_CTRL.CPU_ALIVE_CTRL should be 0 */
			<3	0xE0054	0x00000000	0xFFFFFFFF	0>,
			<1	0xE011C	0x00000000	0xFFFFFFFF	0>,
			<1	0xE0000	0x00000001	0xFFFFFFFF	0>,
			<3	0xE0004	0x00000001	0xFFFFFFFF	0>,
			<1	0xE0008	0x10000000	0xFFFFFFFF	0>,
			<3	0xE000C	0x10000000	0xFFFFFFFF	0>,
			<3	0xE0040	0x00000003	0xFFFFFFFF	0>;

		samsung,npucmd-cpuon64-sfr =
			/* DNC boot up */
			"sfrdnc",
			"sfrdnc",
			"sfrdnc",
			"sfrdnc",
			"sfrdnc",
			"sfrdnc",
			"sfrdnc";
		/*	cmd	offset	value	mask		delay */
		samsung,npucmd-cpuon64-data =
		/* to power on, DNC_CPU_ALIVE_CTRL.CPU_ALIVE_CTRL should be 0 */
			<3	0xE0054	0x00000001	0xFFFFFFFF	0>,
			<1	0xE011C	0x00000000	0xFFFFFFFF	0>,
			<1	0xE0000	0x00000001	0xFFFFFFFF	0>,
			<3	0xE0004	0x00000001	0xFFFFFFFF	0>,
			<1	0xE0008	0x10000000	0xFFFFFFFF	0>,
			<3	0xE000C	0x10000000	0xFFFFFFFF	0>,
			<3	0xE0040	0x00000003	0xFFFFFFFF	0>;

		samsung,npucmd-cpuoff-sfr =
			"sfrdnc";
		samsung,npucmd-cpuoff-data =
		/* to power off NPU cores, HWACG should be enable */
			<3	0xE0040	0x00000000	0xFFFFFFFF	0>;

		samsung,npucmd-freqv-sfr =
			"sfrdnc",
			"sfrblkdnc",
			"sfrblkdnc",
			"sfrblksdma",
			"sfrblksdma",
			"sfrfreq",
			"sfrfreq",
			"sfrfreq",
			"sfrfreq";
		samsung,npucmd-freqv-data =
			<0	0xE00C4	0x00	0xFFFFFFFF	0>,
			<0	0x600	0x00	0xFFFFFFFF	0>,
			<0	0x1804	0x00	0xFFFFFFFF	0>,
			<0	0x600	0x00	0xFFFFFFFF	0>,
			<0	0x1804	0x00	0xFFFFFFFF	0>,
			<0	0x21060	0x00	0xFFFFFFFF	0>,
			<0	0x21158	0x00	0xFFFFFFFF	0>,
			<0	0x2185C	0x00	0xFFFFFFFF	0>,
			<0	0x21930	0x00	0xFFFFFFFF	0>;

		samsung,npucmd-cpupc-sfr =
			"sfrdnc",
			"sfrdnc";
		samsung,npucmd-cpupc-data =
			<0	0xE00CC	0x00	0xFFFFFFFF	0>,
			<0	0xE00D0	0x00	0xFFFFFFFF	0>;

		samsung,npucmd-gnpucmdqpc-sfr =
			"sfrgnpu0",
			"sfrgnpu0",
			"sfrgnpu1",
			"sfrgnpu1";
		samsung,npucmd-gnpucmdqpc-data =
			<0	0x2300	0x00	0xFFFFFFFF	0>,
			<0	0x4300	0x00	0xFFFFFFFF	0>,
			<0	0x2300	0x00	0xFFFFFFFF	0>,
			<0	0x4300	0x00	0xFFFFFFFF	0>;

		samsung,npucmd-dspcmdqpc-sfr =
			"sfrdsp0",
			"sfrdsp0";
		samsung,npucmd-dspcmdqpc-data =
			<0	0x12300	0x00	0xFFFFFFFF	0>,
			<0	0x14300	0x00	0xFFFFFFFF	0>;

		samsung,npucmd-afmdncen-sfr =
			"htudnc",
			"htudnc",
			"htudnc",
			"htudnc",
			"htudnc",
			"htudnc",
			"htudnc",
			"htudnc";
		samsung,npucmd-afmdncen-data =
			<1	0x200	0x00000022	0x00000022	0>,
			<1	0x06C	0x08A00018	0x08E000FC	0>,
			<1	0x080	0x02000001	0xFFF0FFF3	0>,
			<1	0x020	0x00003000	0x00003800	0>,
			<1	0x048	0x3FF0007F	0x3FF000FF	0>,
			<1	0x200	0x80000000	0x80000000	0>,
			<1	0x118	0x80000000	0xFFFFFFFF	0>,
			<1	0x000	0x00000001	0x00000001	0>;

		samsung,npucmd-afmdncdis-sfr =
			"htudnc",
			"htudnc",
			"htudnc",
			"htudnc",
			"htudnc",
			"htudnc",
			"htudnc",
			"htudnc";
		samsung,npucmd-afmdncdis-data =
			<1	0x200	0x00	0x00000022	0>,
			<1	0x06C	0x00	0x08E000FC	0>,
			<1	0x080	0x00	0xFFF0FFF3	0>,
			<1	0x020	0x00	0x00003800	0>,
			<1	0x048	0x00	0x3FF000FF	0>,
			<1	0x200	0x00	0x80000000	0>,
			<1	0x118	0x00	0xFFFFFFFF	0>,
			<1	0x000	0x00	0x00000001	0>;

		samsung,npucmd-afmgnpu1en-sfr =
			"htugnpu1",
			"htugnpu1",
			"htugnpu1",
			"htugnpu1",
			"htugnpu1",
			"htugnpu1",
			"htugnpu1",
			"htugnpu1";
		samsung,npucmd-afmgnpu1en-data =
			<1	0x200	0x00000022	0x00000022	0>,
			<1	0x06C	0x08A00018	0x08E000FC	0>,
			<1	0x080	0x02000001	0xFFF0FFF3	0>,
			<1	0x020	0x00003000	0x00003800	0>,
			<1	0x048	0x3FF0007F	0x3FF000FF	0>,
			<1	0x200	0x80000000	0x80000000	0>,
			<1	0x118	0x80000000	0xFFFFFFFF	0>,
			<1	0x000	0x00000001	0x00000001	0>;

		samsung,npucmd-afmgnpu1dis-sfr =
			"htugnpu1",
			"htugnpu1",
			"htugnpu1",
			"htugnpu1",
			"htugnpu1",
			"htugnpu1",
			"htugnpu1",
			"htugnpu1";
		samsung,npucmd-afmgnpu1dis-data =
			<1	0x200	0x00	0x00000022	0>,
			<1	0x06C	0x00	0x08E000FC	0>,
			<1	0x080	0x00	0xFFF0FFF3	0>,
			<1	0x020	0x00	0x00003800	0>,
			<1	0x048	0x00	0x3FF000FF	0>,
			<1	0x200	0x00	0x80000000	0>,
			<1	0x118	0x00	0xFFFFFFFF	0>,
			<1	0x000	0x00	0x00000001	0>;

		samsung,npucmd-chkdncitr-sfr =
			"htudnc";
		samsung,npucmd-chkdncitr-data =
			<0	0x06C	0x08000000	0x08000000	0>;

		samsung,npucmd-clrdncitr-sfr =
			"htudnc";
		samsung,npucmd-clrdncitr-data =
			<1	0x06C	0x08000000	0x08000000	0>;

		samsung,npucmd-endncitr-sfr =
			"htudnc";
		samsung,npucmd-endncitr-data =
			<1	0x080	0x00000003	0x00000003	0>;

		samsung,npucmd-disdncitr-sfr =
			"htudnc";
		samsung,npucmd-disdncitr-data =
			<1	0x080	0x00	0x00000003	0>;

		samsung,npucmd-clrdnctdc-sfr =
			"htudnc";
		samsung,npucmd-clrdnctdc-data =
			<1	0x080	0x00	0x0000FFF0	0>;

		samsung,npucmd-chkdnctdc-sfr =
			"htudnc";
		samsung,npucmd-chkdnctdc-data =
			<0	0x080	0x00	0x0000FFF0	0>;

		samsung,npucmd-chkgnpu1itr-sfr =
			"htugnpu1";
		samsung,npucmd-chkgnpu1itr-data =
			<0	0x06C	0x08000000	0x08000000	0>;

		samsung,npucmd-clrgnpu1itr-sfr =
			"htugnpu1";
		samsung,npucmd-clrgnpu1itr-data =
			<1	0x06C	0x08000000	0x08000000	0>;

		samsung,npucmd-engnpu1itr-sfr =
			"htugnpu1";
		samsung,npucmd-engnpu1itr-data =
			<1	0x080	0x00000003	0x00000003	0>;

		samsung,npucmd-disgnpu1itr-sfr =
			"htugnpu1";
		samsung,npucmd-disgnpu1itr-data =
			<1	0x080	0x00	0x00000003	0>;

		samsung,npucmd-clrgnpu1tdc-sfr =
			"htugnpu1";
		samsung,npucmd-clrgnpu1tdc-data =
			<1	0x080	0x00	0x0000FFF0	0>;

		samsung,npucmd-chkgnpu1tdc-sfr =
			"htugnpu1";
		samsung,npucmd-chkgnpu1tdc-data =
			<0	0x080	0x00	0x0000FFF0	0>;

		samsung,npucmd-clrdncdiv-sfr =
			"sfrblkdnc",
			"sfrblksdma";
		samsung,npucmd-clrdncdiv-data =
			<1	0x830	0x00	0x00000010	0>,
			<1	0x830	0x00	0x00000010	0>;

		samsung,npucmd-clrgnpu0div-sfr =
			"sfrblkgnpu0";
		samsung,npucmd-clrgnpu0div-data =
			<1	0x830	0x00	0x00000010	0>;

		samsung,npucmd-clrgnpu1div-sfr =
			"sfrblkgnpu1";
		samsung,npucmd-clrgnpu1div-data =
			<1	0x830	0x00	0x00000010	0>;

		samsung,npucmd-clrdspdiv-sfr =
			"sfrblkdsp0";
		samsung,npucmd-clrdspdiv-data =
			<1	0x830	0x00	0x00000010	0>;

		samsung,npucmd-printafmst-sfr =
			"sfrblkdnc",
			"sfrblkdnc",
			"sfrblkdnc",
			"sfrblksdma",
			"sfrblksdma",
			"sfrblksdma",
			"sfrblkgnpu0",
			"sfrblkgnpu0",
			"sfrblkgnpu0";

		samsung,npucmd-printafmst-data =
			<2	0x830	0x00	0xFFFFFFFF	0>,
			<2	0x834	0x00	0xFFFFFFFF	0>,
			<2	0x838	0x00	0xFFFFFFFF	0>,
			<2	0x830	0x00	0xFFFFFFFF	0>,
			<2	0x834	0x00	0xFFFFFFFF	0>,
			<2	0x838	0x00	0xFFFFFFFF	0>,
			<2	0x830	0x00	0xFFFFFFFF	0>,
			<2	0x838	0x00	0xFFFFFFFF	0>,
			<2	0x83C	0x00	0xFFFFFFFF	0>;

		samsung,npucmd-enablestm-sfr =
			"sfrdnc",
			"sfrsdma",
			"sfrgnpu0",
			"sfrgnpu1",
			"sfrsnpu0",
			"sfrsnpu1",
			"sfrdsp0",
			"sfrcoresight",
			"sfrcoresight";
		/*	cmd	offset	value	mask		delay */
		samsung,npucmd-enablestm-data =
			<1	0x20014	0x1	0x00000001	0>,
			<1	0xF800	0x80000000	0x80000000	0>,
			<1	0x10004	0x1	0x00000001	0>,
			<1	0x10004	0x1	0x00000001	0>,
			<1	0x10004	0x1	0x00000001	0>,
			<1	0x10004	0x1	0x00000001	0>,
			<1	0x01E8	0x1	0x00000001	0>,
			<1	0x0034	0x1	0x00000001	0>,
			<1	0x002C	0x1	0x00000001	0>;

		samsung,npucmd-disablestm-sfr =
			"sfrcoresight",
			"sfrcoresight",
			"sfrdsp0",
			"sfrsnpu0",
			"sfrsnpu1",
			"sfrgnpu0",
			"sfrgnpu1",
			"sfrsdma",
			"sfrdnc";
		/*	cmd	offset	value	mask		delay */
		samsung,npucmd-disablestm-data =
			<1	0x002C	0x0	0x00000001	0>,
			<1	0x0034	0x0	0x00000001	0>,
			<1	0x01E8	0x0	0x00000001	0>,
			<1	0x10004	0x0	0x00000001	0>,
			<1	0x10004	0x0	0x00000001	0>,
			<1	0x10004	0x0	0x00000001	0>,
			<1	0x10004	0x0	0x00000001	0>,
			<1	0xF800	0x0	0x80000000	0>,
			<1	0x20014	0x0	0x00000001	0>;

		samsung,npucmd-enstmdnc-sfr =
		/* DNC enable stm */
			"sfrdnc",
			"sfrsdma",
			"sfrcoresight",
			"sfrcoresight";
		/*	cmd	offset	value	mask		delay */
		samsung,npucmd-enstmdnc-data =
		/* DNC enable stm */
			<1	0x20014	0x1	0x00000001	0>,
			<1	0xF800	0x80000000	0x80000000	0>,
			<1	0x0034	0x1	0x00000001	0>,
			<1	0x002C	0x1	0x00000001	0>;

		samsung,npucmd-disstmdnc-sfr =
		/* DNC disable stm */
			"sfrcoresight",
			"sfrcoresight",
			"sfrsdma",
			"sfrdnc";
		/*	cmd	offset	value	mask		delay */
		samsung,npucmd-disstmdnc-data =
		/* DNC disable stm */
			<1	0x002C	0x0	0x00000001	0>,
			<1	0x0034	0x0	0x00000001	0>,
			<1	0xF800	0x0	0x80000000	0>,
			<1	0x20014	0x0	0x00000001	0>;

		samsung,npucmd-enstmdsp-sfr =
		/* DSP enable stm */
			"sfrdsp0";
		/*	cmd	offset	value	mask		delay */
		samsung,npucmd-enstmdsp-data =
		/* DSP enable stm */
			<1	0x01E8	0x1	0x00000001	0>;

		samsung,npucmd-disstmdsp-sfr =
		/* DSP disable stm */
			"sfrdsp0";
		/*	cmd	offset	value	mask		delay */
		samsung,npucmd-disstmdsp-data =
		/* DSP disable stm */
			<1	0x01E8	0x0	0x00000001	0>;

		samsung,npucmd-enstmnpu-sfr =
		/* NPU enable stm */
			"sfrsnpu0",
			"sfrsnpu1",
			"sfrgnpu0",
			"sfrgnpu1";
		/*	cmd	offset	value	mask		delay */
		samsung,npucmd-enstmnpu-data =
		/* NPU enable stm */
			<1	0x10004	0x1	0x00000001	0>,
			<1	0x10004	0x1	0x00000001	0>,
			<1	0x10004	0x1	0x00000001	0>,
			<1	0x10004	0x1	0x00000001	0>;

		samsung,npucmd-disstmnpu-sfr =
		/* NPU disble stm */
			"sfrsnpu0",
			"sfrsnpu1",
			"sfrgnpu0",
			"sfrgnpu1";
		/*	cmd	offset	value	mask		delay */
		samsung,npucmd-disstmnpu-data =
		/* NPU disble stm */
			<1	0x10004	0x0	0x00000001	0>,
			<1	0x10004	0x0	0x00000001	0>,
			<1	0x10004	0x0	0x00000001	0>,
			<1	0x10004	0x0	0x00000001	0>;

		samsung,npucmd-allow64stm-sfr =
			"sfrstm",
			"sfrstm",
			"sfrstm",
			"sfrstm",
			"sfrstm",
			"sfrstm",
			"sfrstm";

		/*	cmd	offset	value	mask		delay */
		samsung,npucmd-allow64stm-data =
			<1	0x0D64	0x0		0xFFFFFFFF	0>,
			<1	0x0D60	0x0		0x00000001	0>,
			<1	0x0D20	0xFFFFFFFF	0xFFFFFFFF	0>,
			<1	0x0D00	0xFFFFFFFF	0xFFFFFFFF	0>,
			<1	0x0D60	0x1		0x00000001	0>,
			<1	0x0D20	0xFFFFFFFF	0xFFFFFFFF	0>,
			<1	0x0D00	0xFFFFFFFF	0xFFFFFFFF	0>;

		samsung,npucmd-fwpwm-sfr =
			"sfrdnc";
		/*	cmd	offset	value	mask		delay */
		samsung,npucmd-fwpwm-data =
			<0	0x5002c	0x00	0xFFFFFFFF	0>;

		samsung,imgloader-s2mpu-support = "true";
		samsung,npusched-tpf-others = <1500>;	/* time in device driver, us */
		samsung,npusched-afmlimit = <800000>;
		samsung,npusched-min-active-cores = <1>; /* FW needs atleast one core to be active */
		samsung,npusched-dvfs =
			/* devfreq      init    delay   up      delay   down    delay
			* hispeed_idle_delay hispeed_delay hispeed_freq lowspeed_idle_delay    : exynos-interactive
			* normal       npu     cpu                             : mode minlock freq
			*/
			<&devfreq_5     1300000	30      120     75      85      75
				30      0       100     100
				1300000	1300000	0	0	1300000	1300000>,
			<&devfreq_6     1300000	30      120     75      85      75
				30      0       100     100
				1300000	1300000	0	0	1300000	1300000>,
			<&devfreq_8     935000	30      120     75      85      30
				30      0       100     100
				935000	935000	0	0	935000	935000>,
			<&devfreq_1	0	0	0	0	0	0
				0	0	0	0
				0	0	0	0	0	0>,
			<&devfreq_0	0	0	0	0	0	0
				0	0	0	0
				0	0	0	0	0	0>,
			<&devfreq_13    1200000	30      120     75      85      75
				30      0       100     100
				1200000	1200000	0	0	1200000	1200000>
			;
		samsung,npusched-names =
			"NPU0",  "exynos-interactive",
			"NPU1",  "exynos-interactive",
			"DNC",  "exynos-interactive",
			"INT",	"",
			"MIF",	"",
			"DSP",  "exynos-interactive"
		;

		samsung,npudvfs-open-dvfs =
			"DNC",
			"NPU0",
			"NPU1",
			"DSP",
			"DSP";
		samsung,npudvfs-open-clock =
			<0	267000>,
			<0	533000>,
			<0	533000>,
			<1	1200000>,
			<0	332000>;

		samsung,npudvfs-close-dvfs =
			"DNC",
			"NPU0",
			"NPU1",
			"DSP";
		samsung,npudvfs-close-clock =
			<0	0>,
			<0	0>,
			<0	0>,
			<0	0>;

		samsung,npudvfs-table-num =
			/* table_index	type_num */
			<11 4>;

		samsung,npudvfs-table =
			/* core      dnc       mif      int */
			<1200000 935000 3738000 664000>,
			<1200000 800000 3172000 533000>,
			<1066000 800000 2730000 400000>,
			<935000 664000 2288000 400000>,
			<800000 533000 2028000 350000>,
			<664000 533000 1716000 350000>,
			<664000 332000 1539000 267000>,
			<533000 267000 1352000 267000>,
			<533000 267000 1014000 200000>,
			<533000 267000 845000 200000>,
			<533000 267000 676000 133000>;

		samsung,npugovernor-num =
			/* npu mif int */
			<8 13 13>;

		samsung,npugovernor-npufreq =
			/* dnc   core */
			<160000 166000>,
			<267000 533000>,
			<533000 664000>,
			<664000 800000>,
			<800000 935000>,
			<800000 1066000>,
			<935000 1200000>,
			<935000 1300000>;

		samsung,npugovernor-miffreq =
			<421000>,
			<676000>,
			<845000>,
			<1014000>,
			<1352000>,
			<1539000>,
			<1716000>,
			<2028000>,
			<2288000>,
			<2730000>,
			<3172000>,
			<3738000>,
			<4206000>;

		samsung,npugovernor-intfreq =
			<134000>,
			<134000>,
			<134000>,
			<134000>,
			<134000>,
			<134000>,
			<200000>,
			<267000>,
			<332000>,
			<400000>,
			<530000>,
			<664000>,
			<800000>;

		samsung,npudtm-param =
			/* target_thermal p_gain i_gain inv_gain period limit_thermal limit_frequncy */
			<93000 300 1 300 1 85000 800000>;

		samsung,npuinter-isr-cpu-affinity = "4-6";

		samsung,npuproto-task-priority = <1>;	/* SCHED_FIFO, 1 */
		samsung,npuproto-task-cpu-affinity = "4-6";

		samsung,npuafm-gnpu0-offset = <0x28>;
		samsung,npuafm-gnpu0-level = <0x00>;
		samsung,npuafm-gnpu1-offset = <0x20>;
		samsung,npuafm-gnpu1-level = <0x00>;

		status = "ok";

		vertex_name = "npu";

		configs =
			<16>,		/* NPU_MAX_BUFFER */
			<3>,		/* NPU_MAX_PLANE */
			<32>,		/* NPU_MAX_GRAPH */
			<16>,		/* NPU_MAX_FRAME */
			<10>,		/* NPU_MINOR */
			<1024>,		/* NW_Q_SIZE */
			<1024>,		/* FRAME_Q_SIZE */
			<4194304>,	/* NPU_FW_LOG_KEEP_SIZE */
			<0>,		/* NPU_MAILBOX_DEFAULT_TID */
			<20>,		/* TCNTO0_OFF */
			<4096>,		/* NPU_MAILBOX_HDR_SECTION_LEN */
			<32768>,	/* NPU_MAILBOX_SIZE */
			<0x80000>,	/* NPU_MAILBOX_BASE */
			<300>,		/* POWER_DOWN_DELAY_ON_EMERGENCY */
			<12000>,	/* STREAMOFF_DELAY_ON_EMERGENCY */
			<0>,		/* NPU_FW_BASE_ADDR */
			<0>,		/* NPU_CM7_RELEASE_HACK */
			<0x50E00000>,	/* NPU_SHARED_MEM_PAYLOAD */
			<0x17EB0000>,	/* NPU_C2AGENT_0 */
			<0x17EC0000>,	/* NPU_C2AGENT_1 */
			<0x15010000>,	/* NPU_VOTF */
			<0x10000>,	/* NPU_VOTF_SIZE */
			<0>,		/* PBHA_HINT_00 */
			<1>,		/* PBHA_HINT_01 */
			<2>,		/* PBHA_HINT_10 */
			<3>,		/* PBHA_HINT_11 */
			<0x80000000>,   /* TRANSACTIONS_PER_CORE */
			<0x02000000>,   /* CMDQ_COMPLEXITY_PER_CORE */
			<1000000>,      /* LASTQ_TIME_THRESHOLD */
			<399>,		/* ALPHA */
			<24684>,	/* BETA */
			<3000>,		/* Time for clk setting */
			<0>,		/* DSP_WAIT_MODE */
			<1000>,		/* DSP_WAIT_RESET */
			<3000>,		/* DSP_WAIT_BOOT */
			<0x40000000>,	/* NPU IMB THRESHOLD SIZE */
			<8>,		/* NPU0 LLC BOOST buffer size in MB */
			<0>,		/* NPU1 LLC BOOST buffer size in MB */
			<0>,		/* NPU2 LLC BOOST buffer size in MB */
			<0x80000>	/* NPU LLC CHUNK  size in Byte */
			;

		samsung,npurmem-address {
			fwmem {
				memory-region = <&dnc_fw_mem>;
				iova = <0x10000000>;
				size =   <0x800000>;
			};
		};
	};

	hwdevdnc: hwdev_dnc {
		compatible = "samsung,exynos-npu-hwdev";

		samsung,npuhwdev-name = "DNC";
		samsung,npuhwdev-id = <NPU_HWDEV_ID_DNC>;

//		clocks = <&clock UMUX_CLKCMU_DNC_NOC>;
//		clock-names = "dnc_noc";

		/* iommu already has parent as <&pd_npus> */
//		power-domains = <&pd_sdma>;

		samsung,npuhwdev-type =
			<(NPU_HWDEV_TYPE_PWRCTRL | NPU_HWDEV_TYPE_CLKCTRL)>;

		iommus = <&sysmmu_sdma_s0>, <&sysmmu_sdma_s1>;
		samsung,iommu-group = <&iommu_group_npu>;
		sysmmu,best-fit;
		#dma-address-cells = <1>;
		#dma-size-cells = <1>;
		dma-window = <0x63000000 0x9D000000>;
		dma-coherent;
		status = "ok";
	};

	hwdevnpu: hwdev_npu {
		compatible = "samsung,exynos-npu-hwdev";

		samsung,npuhwdev-name = "NPU";
		samsung,npuhwdev-id = <NPU_HWDEV_ID_NPU>;
		samsung,npuhwdev-parent = "DNC";
/*
		clocks =
			<&clock UMUX_CLKCMU_NPU0_BUS_USER>;
		clock-names =
			"npu00_bus";
*/
		power-domains = <&pd_snpu1>;

		samsung,npuhwdev-type =
			<(NPU_HWDEV_TYPE_PWRCTRL | NPU_HWDEV_TYPE_CLKCTRL | NPU_HWDEV_TYPE_DVFS)>;

		status = "ok";
	};

	hwdevdsp: hwdev_dsp {
		compatible = "samsung,exynos-npu-hwdev";

		samsung,npuhwdev-name = "DSP";
		samsung,npuhwdev-id = <NPU_HWDEV_ID_DSP>;
		samsung,npuhwdev-parent = "DNC";
/*
		clocks =
			<&clock UMUX_CLKCMU_VPD_BUS_USER>,
			<&clock GATE_IP_VPD_QCH>,
			<&clock DOUT_DIV_CLK_VPD_BUSP>;
		clock-names =
			"umux_clkcmu_vpd_bus_user",
			"gate_ip_vpd_qch",
			"dout_div_clk_vpd_busp";
*/
		power-domains = <&pd_dsp>;

		samsung,npuhwdev-type =
			<(NPU_HWDEV_TYPE_PWRCTRL | NPU_HWDEV_TYPE_CLKCTRL | NPU_HWDEV_TYPE_DVFS)>;

		status = "ok";
	};

	hwdevcl1: hwdev_cl1 {
		compatible = "samsung,exynos-npu-hwdev";

		samsung,npuhwdev-name = "CL1";
		samsung,npuhwdev-id = <NPU_HWDEV_ID_CL1>;

		samsung,npuhwdev-type =
			<NPU_HWDEV_TYPE_DVFS>;

		status = "ok";
	};

	hwdevmif: hwdev_mif {
		compatible = "samsung,exynos-npu-hwdev";

		samsung,npuhwdev-name = "MIF";
		samsung,npuhwdev-id = <NPU_HWDEV_ID_MIF>;

		samsung,npuhwdev-type =
			<NPU_HWDEV_TYPE_BTS>;

		status = "ok";
	};

	hwdevint: hwdev_int {
		compatible = "samsung,exynos-npu-hwdev";

		samsung,npuhwdev-name = "INT";
		samsung,npuhwdev-id = <NPU_HWDEV_ID_INT>;

		samsung,npuhwdev-type =
			<NPU_HWDEV_TYPE_BTS>;

		status = "ok";
	};

	unpu: unpu_exynos {
		compatible = "samsung,exynos-unpu";
		#dma-address-cells = <1>;
		#dma-size-cells = <1>;
		dma-window = <0x63000000 0x9D000000>;
		dma-coherent;

		reg =
		<0 0x15100000 0x10000>,
		<0 0x15110000 0x10000>,
		<0 0x15400000 0x84000>;

		reg-names =
		"unpu_ctrl",
		"yamin_ctrl",
		"unpu_sram";

		samsung,unpu-pmu-offset = <0x3700>;
		power-domains = <&pd_unpu>;
	};
};
